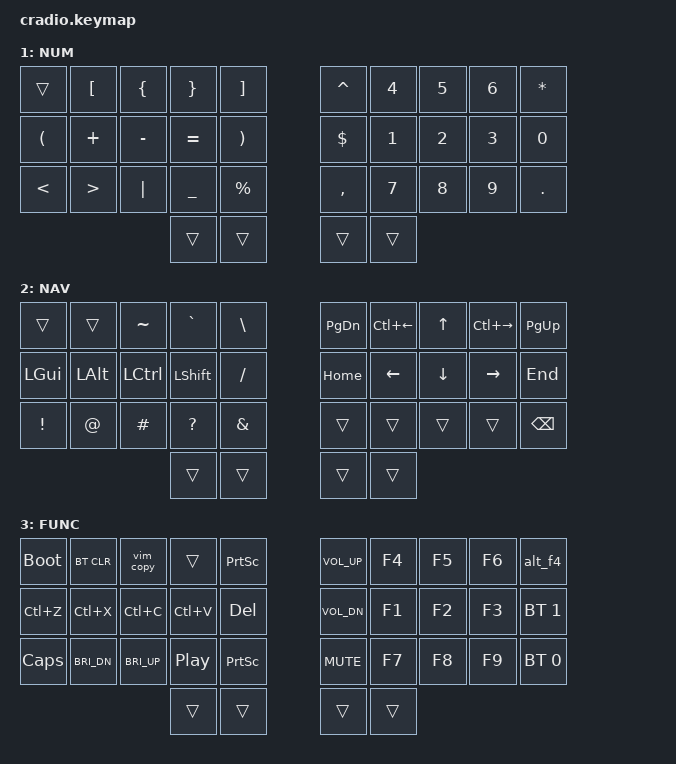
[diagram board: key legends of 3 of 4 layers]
// Copyright (c) 2022 The ZMK Contributors
// SPDX-License-Identifier: MIT

#include <behaviors.dtsi>
#include <dt-bindings/zmk/keys.h>
#include <dt-bindings/zmk/bt.h>

// Home row mods macro
#define HRML(k1,k2,k3,k4) &ht LGUI k1 &ht LALT k2  &ht LCTRL k3  &ht LSHFT k4
#define HRMR(k1,k2,k3,k4) &ht RSHFT k1  &ht RCTRL k2  &ht RALT k3  &ht RGUI k4


/ {
    behaviors {
        ht: hold_tap {
            compatible = "zmk,behavior-hold-tap";
            #binding-cells = <2>;
            flavor = "tap-preferred";
            tapping-term-ms = <200>;
            quick-tap-ms = <150>;
            require-prior-idle-ms = <100>;
            bindings = <&kp>, <&kp>;
        };
        alt_f4: alt_f4 {
            compatible = "zmk,behavior-macro";
            label = "Alt + F4";
            #binding-cells = <0>;
            bindings = <&kp LALT &kp F4>;
        };
        vim_copy: vim_copy {
            compatible = "zmk,behavior-macro";
            label = "Vim Copy";
            #binding-cells = <0>;
            bindings = <&kp DQT>, <&kp PLUS>, <&kp Y>;
        };
    };

    conditional_layers {
        compatible = "zmk,conditional-layers";
        FUNC {
            if-layers = <1 2>;
            then-layer = <3>;
        };
    };

    keymap {
        compatible = "zmk,keymap";
        DEFAULT {
            bindings = <
        //╭──────────┬──────────┬──────────┬──────────┬──────────╮   ╭──────────┬──────────┬──────────┬──────────┬──────────╮
        //│  X       │  F       │  D       │  P       │  Q       │   │  J       │  '       │  O       │  U       │ ENTER    │
            &kp X      &kp F      &kp D      &kp P      &kp Q          &kp J      &kp SQT    &kp O      &kp U      &kp ENTER
        //├──────────┼──────────┼──────────┼──────────┼──────────┤   ├──────────┼──────────┼──────────┼──────────┼──────────┤
        //│  N       │  S       │  T       │  C       │  Y       │   │  M       │  H       │  A       │  E       │ I        │
            HRML(N,        S,         T,         C)     &kp Y          &kp M      HRMR(H,        A,         E,        I)
        //├──────────┼──────────┼──────────┼──────────┼──────────┤   ├──────────┼──────────┼──────────┼──────────┼──────────┤
        //│  B       │  V       │  K       │  G       │  W       │   │  Z       │  L       │ :        │ .        │ ,        │
            &kp B      &kp V      &kp K      &kp G      &kp W          &kp Z      &kp L      &kp COLON  &kp DOT    &kp COMMA
        //╰──────────┴──────────┴──────────┼──────────┼──────────┤   ├──────────┼──────────┼──────────┴──────────┴──────────╯
                                            &lt 1 TAB  &kp SPACE      &kp ESCAPE &lt 2 R
        //                                 ╰──────────┴──────────╯   ╰──────────┴──────────╯
            >;
        };

        NUM {
            bindings = <
        //╭──────────┬──────────┬──────────┬──────────┬──────────╮   ┌──────────┬──────────┬──────────┬──────────┬──────────╮
        //│          │          │          │          │          │   │ ^        |  4       │  5       │  6       │ *        |
           &trans     &kp LBKT   &kp LBRC   &kp RBRC   &kp RBKT       &kp CARET  &kp N4     &kp N5     &kp N6      &kp ASTRK
        //├──────────┼──────────┼──────────┼──────────┼──────────┤   ├──────────┼──────────┼──────────┼──────────┼──────────┤
        //│          │          │          │          │          │   │ $        │  1       │  2       │  3       │  0       │
           &kp LPAR   &kp PLUS   &kp MINUS  &kp EQUAL  &kp RPAR       &kp DLLR   &kp N1     &kp N2     &kp N3     &kp N0      
        //├──────────┼──────────┼──────────┼──────────┼──────────┤   ├──────────┼──────────┼──────────┼──────────┼──────────┤
        //│          │          │          │          │          │   │  ,       | 7        │  8       │  9       │ .        │
           &kp LT     &kp GT     &kp PIPE   &kp UNDER  &kp PRCNT      &kp COMMA  &kp N7     &kp N8     &kp N9     &kp DOT     
        //╰──────────┴──────────┴──────────┼──────────┼──────────┤   ├──────────┼──────────┼──────────┴──────────┴──────────╯
                                             &trans     &trans        &trans      &trans
        //                                 ╰──────────┴──────────╯   ╰──────────┴──────────╯
            >;
        };

        NAV {
            bindings = <
        //╭──────────┬──────────┬──────────┬──────────┬──────────╮   ╭──────────┬──────────┬──────────┬──────────┬──────────╮
        //│          │          │          │          │          │   │ PAGE DOWN│ BACK    │ UP       │ END      │ PAGE UP  │
           &trans     &trans     &kp TILDE  &kp GRAVE  &kp BSLH       &kp PG_DN  &kp LC(LEFT) &kp UP  &kp LC(RIGHT) &kp PG_UP 
        //├──────────┼──────────┼──────────┼──────────┼──────────┤   ├──────────┼──────────┼──────────┼──────────┼──────────┤
        //│          │          │          │          │          │   │ HOME     │ LEFT     │ DOWN     │ RIGHT    │ END      │
           &kp LGUI   &kp LALT   &kp LCTRL  &kp LSHFT  &kp SLASH       &kp HOME   &kp LEFT   &kp DOWN   &kp RIGHT  &kp END
        //├──────────┼──────────┼──────────┼──────────┼──────────┤   ├──────────┼──────────┼──────────┼──────────┼──────────┤
        //│          │          │          │          │          │   │          │          │          │          │          │
           &kp EXCL   &kp AT     &kp HASH   &kp QMARK  &kp AMPS       &trans     &trans     &trans     &trans     &kp BSPC
        //╰──────────┴──────────┴──────────┼──────────┼──────────┤   ├──────────┼──────────┼──────────┴──────────┴──────────╯
                                             &trans    &trans        &trans     &trans
        //                                 ╰──────────┴──────────╯   ╰──────────┴──────────╯
            >;
        };

        FUNC {
            bindings = <
        //╭──────────┬──────────┬──────────┬──────────┬──────────╮   ╭──────────┬──────────┬──────────┬──────────┬──────────╮
        //│BOOTLOADER│ CLEAR BT │ VIM COPY │          │ Print Sc │   │ VOL UP   │  F4      │  F5      │  F6      | alt f4
      &bootloader &bt BT_CLR     &vim_copy  &trans     &kp PSCRN      &kp C_VOL_UP &kp F4     &kp F5     &kp F6    &alt_f4
        //├──────────┼──────────┼──────────┼──────────┼──────────┤   ├──────────┼──────────┼──────────┼──────────┼──────────┤
        //│UNDO      │ CUT      │ COPY     │ PASTE    │          │   │ VOL DOWN │  F1      │  F2      │  F3      |          │
           &kp LC(Z)  &kp LC(X)  &kp LC(C)  &kp LC(V)  &kp DELETE      &kp C_VOL_DN &kp F1     &kp F2     &kp F3   &bt BT_SEL 1
        //├──────────┼──────────┼──────────┼──────────┼──────────┤   ├──────────┼──────────┼──────────┼──────────┼──────────┤
        //│Caps Lock │ Bri Down │ Bri Up   │Play/Pause│ Print Sc │   │ MUTE     │  F7      │  F8      │  F9      │          │
           &kp CAPS   &kp C_BRI_DN &kp C_BRI_UP &kp C_PP &kp PSCRN    &kp C_MUTE &kp F7     &kp F8     &kp F9     &bt BT_SEL 0
        //╰──────────┴──────────┴──────────┼──────────┼──────────┤   ├──────────┼──────────┼──────────┴──────────┴──────────╯
                                             &trans     &trans         &trans    &trans
        //                                 ╰──────────┴──────────╯   ╰──────────┴──────────╯
            >;
        };
    };
};
